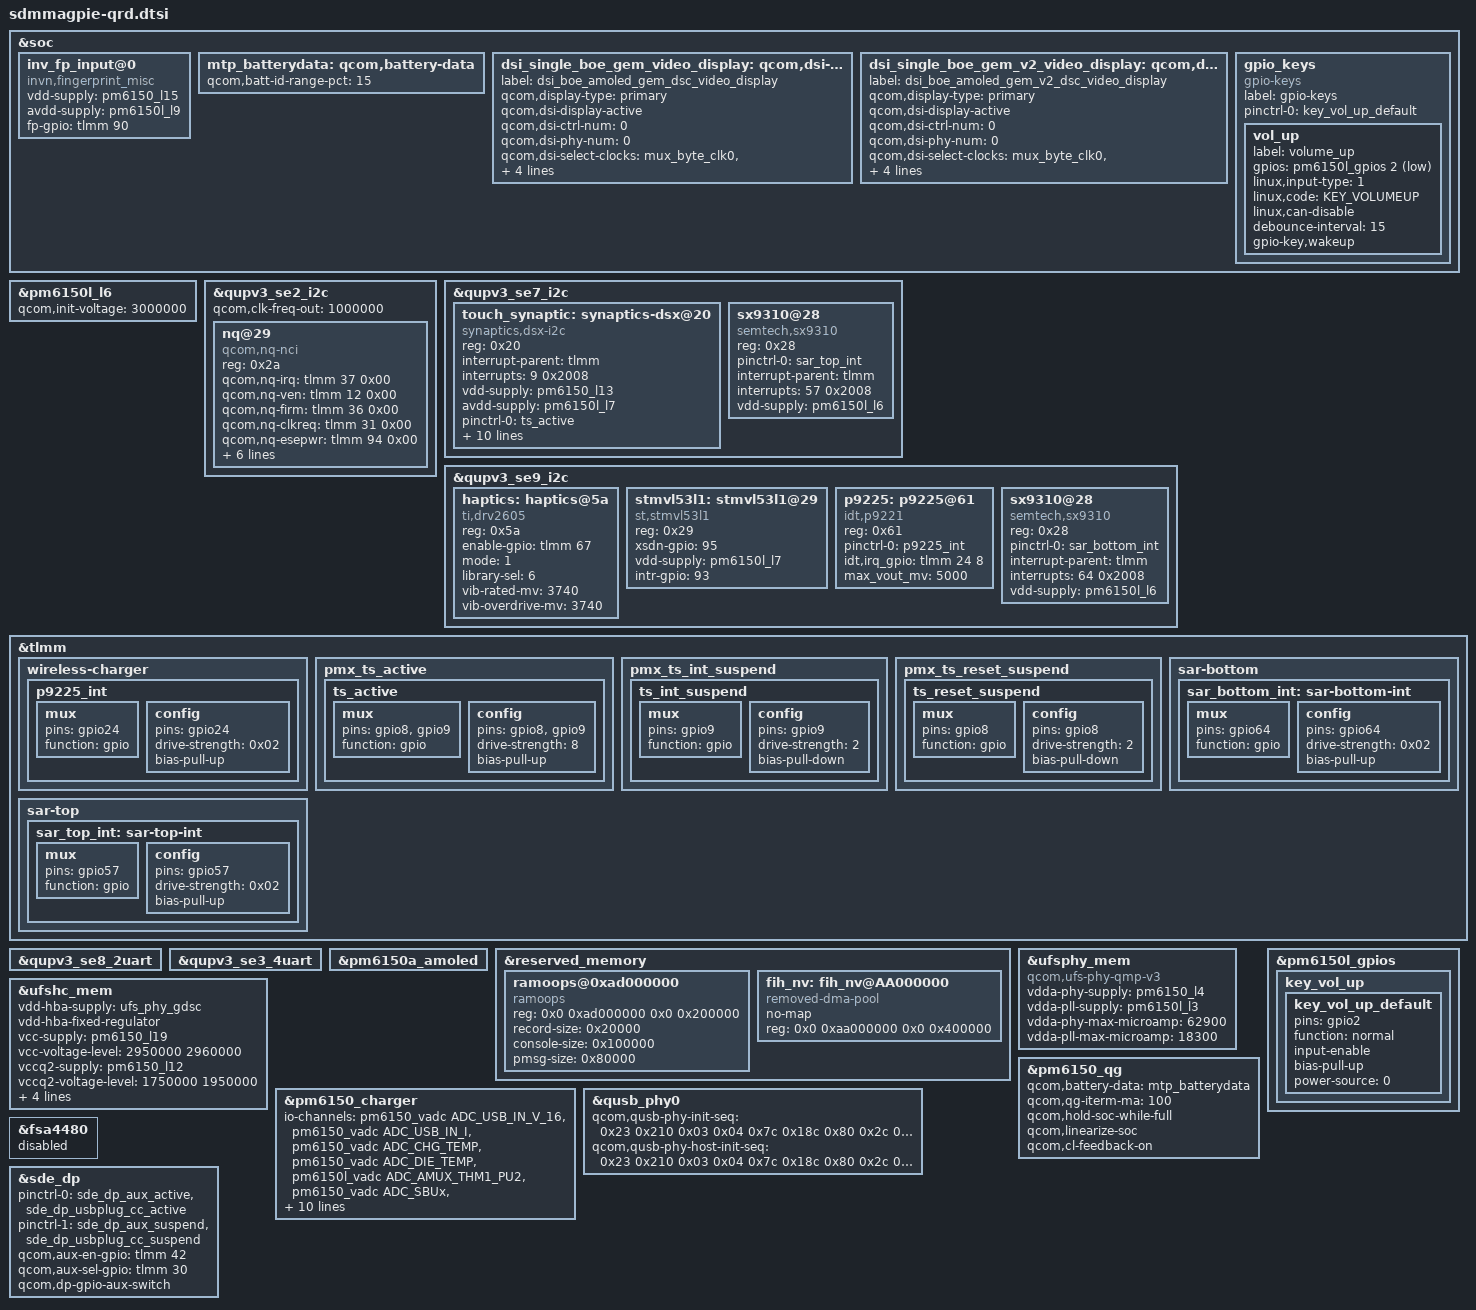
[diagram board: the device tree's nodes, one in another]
/* Copyright (c) 2018-2019, The Linux Foundation. All rights reserved.
 *
 * This program is free software; you can redistribute it and/or modify
 * it under the terms of the GNU General Public License version 2 and
 * only version 2 as published by the Free Software Foundation.
 *
 * This program is distributed in the hope that it will be useful,
 * but WITHOUT ANY WARRANTY; without even the implied warranty of
 * MERCHANTABILITY or FITNESS FOR A PARTICULAR PURPOSE.  See the
 * GNU General Public License for more details.
 */

#include <dt-bindings/gpio/gpio.h>
#include <dt-bindings/pinctrl/qcom,pmic-gpio.h>
#include <dt-bindings/iio/qcom,spmi-vadc.h>
#include <dt-bindings/input/input.h>
#include "sdmmagpie-thermal-overlay.dtsi"

#include "sdmmagpie-sde-display.dtsi"
#include "sdmmagpie-camera-sensor-qrd.dtsi"
#include "../essential/dsi-panel-single-boe-gem-video.dtsi"

&soc {
	inv_fp_input@0 {
		compatible = "invn,fingerprint_misc";
		vdd-supply = <&pm6150_l15>;
		avdd-supply = <&pm6150l_l9>;
		fp-gpio = <&tlmm 90 0>;
	};

	mtp_batterydata: qcom,battery-data {
		qcom,batt-id-range-pct = <15>;
		//#include "qg-batterydata-alium-3600mah.dtsi"
		//#include "qg-batterydata-mlp466076-3200mah.dtsi"
	};
};

&pm6150l_l6 {
	qcom,init-voltage = <3000000>;
};

&qupv3_se2_i2c {
	status = "ok";
	qcom,clk-freq-out = <1000000>;
	nq@29 {
		compatible = "qcom,nq-nci";
		reg = <0x2a>;
		qcom,nq-irq = <&tlmm 37 0x00>;
		qcom,nq-ven = <&tlmm 12 0x00>;
		qcom,nq-firm = <&tlmm 36 0x00>;
		qcom,nq-clkreq = <&tlmm 31 0x00>;
		qcom,nq-esepwr = <&tlmm 94 0x00>;
		interrupt-parent = <&tlmm>;
		interrupts = <37 0>;
		interrupt-names = "nfc_irq";
		pinctrl-names = "nfc_active", "nfc_suspend";
		pinctrl-0 = <&nfc_int_active &nfc_enable_active
				&nfc_clk_req_active>;
		pinctrl-1 = <&nfc_int_suspend &nfc_enable_suspend
				&nfc_clk_req_suspend>;
	};
};

&qupv3_se7_i2c{
	status = "okay";

	touch_synaptic: synaptics-dsx@20 {
		compatible = "synaptics,dsx-i2c";
		reg = <0x20>;
		interrupt-parent = <&tlmm>;
		interrupts = <9 0x2008>;
		vdd-supply = <&pm6150_l13>;
		avdd-supply = <&pm6150l_l7>;
		pinctrl-names = "pmx_ts_active", "pmx_ts_suspend";
		pinctrl-0 = <&ts_active>;
		pinctrl-1 = <&ts_int_suspend>;
		synaptics,pwr-reg-name = "avdd";
		synaptics,bus-reg-name = "vdd";
		synaptics,irq-gpio = <&tlmm 9 0x2008>;
		synaptics,irq-on-state = <0>;
		synaptics,power-delay-ms = <100>;
		synaptics,reset-gpio = <&tlmm 8 0x2008>;
		synaptics,reset-delay-ms = <100>;
		synaptics,reset-on-state = <0>;
		synaptics,reset-active-ms = <20>;
	};

	sx9310@28 {
		compatible = "semtech,sx9310";
		reg = <0x28>;
		pinctrl-names = "default";
		pinctrl-0 = <&sar_top_int>;
		interrupt-parent = <&tlmm>;
		interrupts = <57 0x2008>;
		vdd-supply = <&pm6150l_l6>;
	};
};

&qupv3_se9_i2c {
	status = "okay";

	haptics: haptics@5a {
		compatible = "ti,drv2605";
		reg = <0x5a>;
		enable-gpio = <&tlmm 67 0>;
		mode = <1>;
		library-sel = <6>;
		vib-rated-mv = <3740>;
		vib-overdrive-mv = <3740>;
	};

	stmvl53l1: stmvl53l1@29 {
		compatible = "st,stmvl53l1";
		reg = <0x29>;
		xsdn-gpio = <95>;
		vdd-supply = <&pm6150l_l7>;
		intr-gpio = <93>;
	};

	p9225: p9225@61 {
		compatible = "idt,p9221";
		reg = <0x61>;
		pinctrl-names = "default";
		pinctrl-0 = <&p9225_int>;
		idt,irq_gpio = <&tlmm 24 8>;
		max_vout_mv = <5000>;
	};

	sx9310@28 {
		compatible = "semtech,sx9310";
		reg = <0x28>;
		pinctrl-names = "default";
		pinctrl-0 = <&sar_bottom_int>;
		interrupt-parent = <&tlmm>;
		interrupts = <64 0x2008>;
		vdd-supply = <&pm6150l_l6>;
	};
};

&tlmm {
	wireless-charger {
		p9225_int: p9225_int {
			mux {
				pins = "gpio24";
				function = "gpio";
			};

			config {
				pins = "gpio24";
				drive-strength = <0x02>;
				bias-pull-up;
			};
		};
	};

	pmx_ts_active {
		ts_active: ts_active {
			mux {
				pins = "gpio8", "gpio9";
				function = "gpio";
			};

			config {
				pins = "gpio8", "gpio9";
				drive-strength = <8>;
				bias-pull-up;
			};
		};
	};

	pmx_ts_int_suspend {
		ts_int_suspend: ts_int_suspend {
			mux {
				pins = "gpio9";
				function = "gpio";
			};

			config {
				pins = "gpio9";
				drive-strength = <2>;
				bias-pull-down;
			};
		};
	};

	pmx_ts_reset_suspend {
		ts_reset_suspend: ts_reset_suspend {
				mux {
					pins = "gpio8";
					function = "gpio";
				};

				config {
					pins = "gpio8";
					drive-strength = <2>;
					bias-pull-down;
				};
			};
	};

	sar-bottom {
		sar_bottom_int: sar-bottom-int {
			mux {
				pins = "gpio64";
				function = "gpio";
			};

			config {
				pins = "gpio64";
				drive-strength = <0x02>;
				bias-pull-up;
			};
		};
	};

	sar-top {
		sar_top_int: sar-top-int {
			mux {
				pins = "gpio57";
				function = "gpio";
			};

			config {
				pins = "gpio57";
				drive-strength = <0x02>;
				bias-pull-up;
			};
		};
	};
};

&qupv3_se8_2uart {
	status = "ok";
};

&qupv3_se3_4uart {
	status = "ok";
};

&pm6150a_amoled {
	status = "ok";
};

&reserved_memory {
	ramoops@0xad000000 {
		compatible = "ramoops";
		reg = <0x0 0xad000000 0x0 0x200000>;
		record-size = <0x20000>;
		console-size = <0x100000>;
		pmsg-size = <0x80000>;
	};

	fih_nv: fih_nv@AA000000 {
		compatible = "removed-dma-pool";
		no-map;
		reg = <0x0 0xaa000000 0x0 0x400000>;
	};
};

&ufsphy_mem {
	compatible = "qcom,ufs-phy-qmp-v3";

	vdda-phy-supply = <&pm6150_l4>; /* 0.88v */
	vdda-pll-supply = <&pm6150l_l3>; /* 1.2v */
	vdda-phy-max-microamp = <62900>;
	vdda-pll-max-microamp = <18300>;

	status = "ok";
};

&ufshc_mem {
	vdd-hba-supply = <&ufs_phy_gdsc>;
	vdd-hba-fixed-regulator;
	vcc-supply = <&pm6150_l19>;
	vcc-voltage-level = <2950000 2960000>;
	vccq2-supply = <&pm6150_l12>;
	vccq2-voltage-level = <1750000 1950000>;
	vcc-max-microamp = <600000>;
	vccq2-max-microamp = <600000>;

	qcom,vddp-ref-clk-supply = <&pm6150l_l3>;
	qcom,vddp-ref-clk-max-microamp = <100>;

	status = "ok";
};

&pm6150_qg {
	qcom,battery-data = <&mtp_batterydata>;
	qcom,qg-iterm-ma = <100>;
	qcom,hold-soc-while-full;
	qcom,linearize-soc;
	qcom,cl-feedback-on;
};

&pm6150_charger {
	io-channels = <&pm6150_vadc ADC_USB_IN_V_16>,
		      <&pm6150_vadc ADC_USB_IN_I>,
		      <&pm6150_vadc ADC_CHG_TEMP>,
		      <&pm6150_vadc ADC_DIE_TEMP>,
		      <&pm6150l_vadc ADC_AMUX_THM1_PU2>,
		      <&pm6150_vadc ADC_SBUx>,
		      <&pm6150_vadc ADC_VPH_PWR>;
	io-channel-names = "usb_in_voltage",
			   "usb_in_current",
			   "chg_temp",
			   "die_temp",
			   "conn_temp",
			   "sbux_res",
			   "vph_voltage";
	qcom,battery-data = <&mtp_batterydata>;
	qcom,auto-recharge-soc = <98>;
	qcom,sw-jeita-enable;
	qcom,fcc-stepping-enable;
	qcom,suspend-input-on-debug-batt;
	qcom,sec-charger-config = <1>;
	qcom,thermal-mitigation = <4200000 3500000 3000000
			2500000 2000000 1500000 1000000 500000>;
	dpdm-supply = <&qusb_phy0>;
};

&pm6150l_gpios {
	key_vol_up {
		key_vol_up_default: key_vol_up_default {
			pins = "gpio2";
			function = "normal";
			input-enable;
			bias-pull-up;
			power-source = <0>;
		};
	};
};

&soc {
	dsi_single_boe_gem_video_display: qcom,dsi-display@17 {
		label = "dsi_boe_amoled_gem_dsc_video_display";
		qcom,display-type = "primary";
		qcom,dsi-display-active;
		qcom,dsi-ctrl-num = <0>;
		qcom,dsi-phy-num = <0>;
		qcom,dsi-select-clocks = "mux_byte_clk0", "mux_pixel_clk0",
			"src_byte_clk0", "src_pixel_clk0",
			"shadow_byte_clk0", "shadow_pixel_clk0";
		qcom,dsi-panel = <&dsi_single_boe_gem_video>;
	};

	dsi_single_boe_gem_v2_video_display: qcom,dsi-display@18 {
		label = "dsi_boe_amoled_gem_v2_dsc_video_display";
		qcom,display-type = "primary";
		qcom,dsi-display-active;
		qcom,dsi-ctrl-num = <0>;
		qcom,dsi-phy-num = <0>;
		qcom,dsi-select-clocks = "mux_byte_clk0", "mux_pixel_clk0",
			"src_byte_clk0", "src_pixel_clk0",
			"shadow_byte_clk0", "shadow_pixel_clk0";
		qcom,dsi-panel = <&dsi_single_boe_gem_v2_video>;
	};

	gpio_keys {
		compatible = "gpio-keys";
		label = "gpio-keys";

		pinctrl-names = "default";
		pinctrl-0 = <&key_vol_up_default>;

		vol_up {
			label = "volume_up";
			gpios = <&pm6150l_gpios 2 GPIO_ACTIVE_LOW>;
			linux,input-type = <1>;
			linux,code = <KEY_VOLUMEUP>;
			linux,can-disable;
			debounce-interval = <15>;
			gpio-key,wakeup;
		};
	};
};

&qusb_phy0 {
	qcom,qusb-phy-init-seq =
		/* <value reg_offset> */
		   <0x23 0x210 /* PWR_CTRL1 */
		    0x03 0x04  /* PLL_ANALOG_CONTROLS_TWO */
		    0x7c 0x18c /* PLL_CLOCK_INVERTERS */
		    0x80 0x2c  /* PLL_CMODE */
		    0x0a 0x184 /* PLL_LOCK_DELAY */
		    0x19 0xb4  /* PLL_DIGITAL_TIMERS_TWO */
		    0x40 0x194 /* PLL_BIAS_CONTROL_1 */
		    0x20 0x198 /* PLL_BIAS_CONTROL_2 */
		    0x21 0x214 /* PWR_CTRL2 */
		    0x00 0x220 /* IMP_CTRL1 */
		    0x18 0x224 /* IMP_CTRL2 */
		    0x37 0x240 /* TUNE1 */
		    0x29 0x244 /* TUNE2 */
		    0xca 0x248 /* TUNE3 */
		    0x04 0x24c /* TUNE4 */
		    0x03 0x250 /* TUNE5 */
		    0x00 0x23c /* CHG_CTRL2 */
		    0x22 0x210>; /* PWR_CTRL1 */

	qcom,qusb-phy-host-init-seq =
		/* <value reg_offset> */
		   <0x23 0x210 /* PWR_CTRL1 */
		    0x03 0x04  /* PLL_ANALOG_CONTROLS_TWO */
		    0x7c 0x18c /* PLL_CLOCK_INVERTERS */
		    0x80 0x2c  /* PLL_CMODE */
		    0x0a 0x184 /* PLL_LOCK_DELAY */
		    0x19 0xb4  /* PLL_DIGITAL_TIMERS_TWO */
		    0x40 0x194 /* PLL_BIAS_CONTROL_1 */
		    0x20 0x198 /* PLL_BIAS_CONTROL_2 */
		    0x21 0x214 /* PWR_CTRL2 */
		    0x00 0x220 /* IMP_CTRL1 */
		    0x18 0x224 /* IMP_CTRL2 */
		    0x37 0x240 /* TUNE1 */
		    0x29 0x244 /* TUNE2 */
		    0xca 0x248 /* TUNE3 */
		    0x04 0x24c /* TUNE4 */
		    0x03 0x250 /* TUNE5 */
		    0x00 0x23c /* CHG_CTRL2 */
		    0x22 0x210>; /* PWR_CTRL1 */
};

&fsa4480 {
	status = "disabled";
};

&sde_dp {
	pinctrl-names = "mdss_dp_active", "mdss_dp_sleep";
	pinctrl-0 = <&sde_dp_aux_active &sde_dp_usbplug_cc_active>;
	pinctrl-1 = <&sde_dp_aux_suspend &sde_dp_usbplug_cc_suspend>;
	qcom,aux-en-gpio = <&tlmm 42 0>;
	qcom,aux-sel-gpio = <&tlmm 30 0>;
	qcom,dp-gpio-aux-switch;
};
